# I2C register map
Vendor: Texas Instruments
Peripheral module from a debugger description file (folder CC2650).
Registers are 32-bit, access per field, reset 0x0 unless marked. A register's access mark holds for its fields unless they carry their own. Offsets are as the file gives them; lines under a group give offsets from that group; [hi:lo] are bit positions; {n}, {i} and the like mark numbered series; 'fields as' and 'values as' point back to an identical list; <NAME> marks a mode.

## I2C — I2CMaster/Slave Serial Controler
0x00 SOAR — Slave Own Address This register consists of seven address bits that identify this I2C device on the I2C bus.
  [6:0] OAR rw — I2C slave own address This field specifies bits a6 through a0 of the slave address.
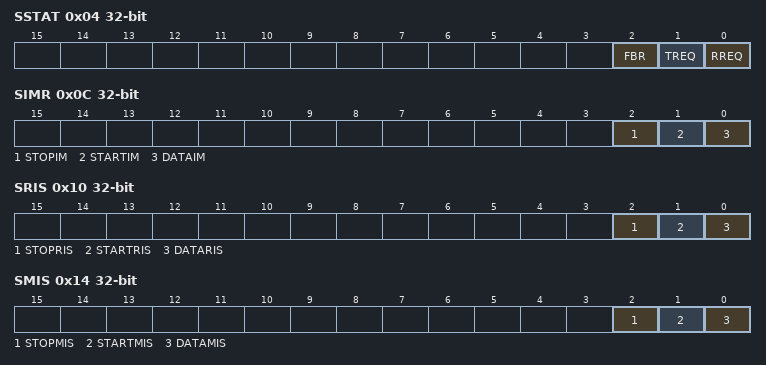
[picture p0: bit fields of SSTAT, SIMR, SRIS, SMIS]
0x04 SSTAT ro — Slave Status Internal Note: This register shares address with SCTL, meaning that this register functions as a control register when written, and a status register when read.
  [2] FBR — First byte received 0: The first byte has not been received. 1: The first byte following the slave's own address has been received. This bit is only valid when the RREQ bit is set and is automatically cleared when data has been read from the SDR register. Note: This bit is not used for slave transmit operations.
  [1] TREQ — Transmit request 0: No outstanding transmit request. 1: The I2C controller has been addressed as a slave transmitter and is using clock stretching to delay the master until data has been written to the SDR register.
  [0] RREQ — Receive request 0: No outstanding receive data 1: The I2C controller has outstanding receive data from the I2C master and is using clock stretching to delay the master until data has been read from the SDR register.
0x04 SCTL wo — Slave Control Note: This register shares address with SSTAT, meaning that this register functions as a control register when written, and a status register when read.
  [0] DA — Device active 0: Disables the I2C slave operation 1: Enables the I2C slave operation
0x08 SDR — Slave Data This register contains the data to be transmitted when in the Slave Transmit state, and the data received when in the Slave Receive state.
  [7:0] DATA rw — Data for transfer This field contains the data for transfer during a slave receive or transmit operation. When written the register data is used as transmit data. When read, this register returns the last data received. Data is stored until next update, either by a system write for transmit or by an external master for receive.
0x0C SIMR — Slave Interrupt Mask This register controls whether a raw interrupt is promoted to a controller interrupt.
  [2] STOPIM rw — Stop condition interrupt mask 0: The SRIS.STOPRIS interrupt is suppressed and not sent to the interrupt controller. 1: The SRIS.STOPRIS interrupt is enabled and sent to the interrupt controller.
    1=EN (Enable Interrupt); 0=DIS (Disable Interrupt)
  [1] STARTIM rw — Start condition interrupt mask 0: The SRIS.STARTRIS interrupt is suppressed and not sent to the interrupt controller. 1: The SRIS.STARTRIS interrupt is enabled and sent to the interrupt controller.
    1=EN (Enable Interrupt); 0=DIS (Disable Interrupt)
  [0] DATAIM rw — Data interrupt mask 0: The SRIS.DATARIS interrupt is suppressed and not sent to the interrupt controller. 1: The SRIS.DATARIS interrupt is enabled and sent to the interrupt controller.
0x10 SRIS ro — Slave Raw Interrupt Status This register shows the unmasked interrupt status.
  [2] STOPRIS — Stop condition raw interrupt status 0: No interrupt 1: A Stop condition interrupt is pending. This bit is cleared by writing a 1 to SICR.STOPIC.
  [1] STARTRIS — Start condition raw interrupt status 0: No interrupt 1: A Start condition interrupt is pending. This bit is cleared by writing a 1 to SICR.STARTIC.
  [0] DATARIS — Data raw interrupt status 0: No interrupt 1: A data received or data requested interrupt is pending. This bit is cleared by writing a 1 to the SICR.DATAIC.
0x14 SMIS ro — Slave Masked Interrupt Status This register show which interrupt is active (based on result from SRIS and SIMR).
  [2] STOPMIS — Stop condition masked interrupt status 0: An interrupt has not occurred or is masked/disabled. 1: An unmasked Stop condition interrupt is pending. This bit is cleared by writing a 1 to the SICR.STOPIC.
  [1] STARTMIS — Start condition masked interrupt status 0: An interrupt has not occurred or is masked/disabled. 1: An unmasked Start condition interrupt is pending. This bit is cleared by writing a 1 to the SICR.STARTIC.
  [0] DATAMIS — Data masked interrupt status 0: An interrupt has not occurred or is masked/disabled. 1: An unmasked data received or data requested interrupt is pending. This bit is cleared by writing a 1 to the SICR.DATAIC.
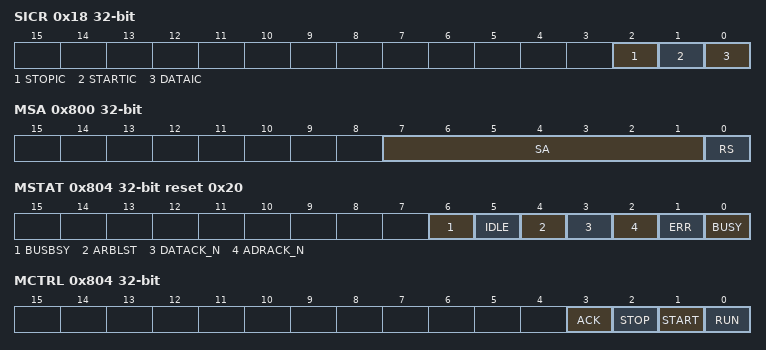
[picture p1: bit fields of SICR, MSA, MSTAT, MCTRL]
0x18 SICR wo — Slave Interrupt Clear This register clears the raw interrupt SRIS.
  [2] STOPIC — Stop condition interrupt clear Writing 1 to this bit clears SRIS.STOPRIS and SMIS.STOPMIS.
  [1] STARTIC — Start condition interrupt clear Writing 1 to this bit clears SRIS.STARTRIS SMIS.STARTMIS.
  [0] DATAIC — Data interrupt clear Writing 1 to this bit clears SRIS.DATARIS SMIS.DATAMIS.
0x800 MSA — Master Salve Address This register contains seven address bits of the slave to be accessed by the master (a6-a0), and an RS bit determining if the next operation is a receive or transmit.
  [7:1] SA rw — I2C master slave address Defines which slave is addressed for the transaction in master mode
  [0] RS rw — Receive or Send This bit-field specifies if the next operation is a receive (high) or a transmit/send (low) from the addressed slave SA.
    1=RX (Receive data from slave); 0=TX (Transmit/send data to slave)
0x804 MSTAT ro reset 0x20 — Master Status
  [6] BUSBSY — Bus busy 0: The I2C bus is idle. 1: The I2C bus is busy. The bit changes based on the MCTRL.START and MCTRL.STOP conditions.
  [5] IDLE — I2C idle 0: The I2C controller is not idle. 1: The I2C controller is idle.
  [4] ARBLST — Arbitration lost 0: The I2C controller won arbitration. 1: The I2C controller lost arbitration.
  [3] DATACK_N — Data Was Not Acknowledge 0: The transmitted data was acknowledged. 1: The transmitted data was not acknowledged.
  [2] ADRACK_N — Address Was Not Acknowledge 0: The transmitted address was acknowledged. 1: The transmitted address was not acknowledged.
  [1] ERR — Error 0: No error was detected on the last operation. 1: An error occurred on the last operation.
  [0] BUSY — I2C busy 0: The controller is idle. 1: The controller is busy. When this bit-field is set, the other status bits are not valid. Note: The I2C controller requires four SYSBUS clock cycles to assert the BUSY status after I2C master operation has been initiated through MCTRL register. Hence after programming MCTRL register, application is requested to wait for four SYSBUS clock cycles before issuing a controller status inquiry through MSTAT register. Any prior inquiry would result in wrong status being reported.
0x804 MCTRL wo — Master Control This register accesses status bits when read and control bits when written. When read, the status register indicates the state of the I2C bus controller as stated in MSTAT. When written, the control register configures the I2C controller operation. To generate a single transmit cycle, the I2C Master Slave Address (MSA) register is written with the desired address, the MSA.RS bit is cleared, and this register is written with * ACK=X (0 or 1), * STOP=1, * START=1, * RUN=1 to perform the operation and stop. When the operation is completed (or aborted due an error), an interrupt becomes active and the data may be read from the MDR register.
  [3] ACK — Data acknowledge enable 0: The received data byte is not acknowledged automatically by the master. 1: The received data byte is acknowledged automatically by the master. This bit-field must be cleared when the I2C bus controller requires no further data to be transmitted from the slave transmitter.
    1=EN (Enable acknowledge); 0=DIS (Disable acknowledge)
  [2] STOP — This bit-field determines if the cycle stops at the end of the data cycle or continues on to a repeated START condition. 0: The controller does not generate the Stop condition. 1: The controller generates the Stop condition.
    1=EN (Enable STOP); 0=DIS (Disable STOP)
  [1] START — This bit-field generates the Start or Repeated Start condition. 0: The controller does not generate the Start condition. 1: The controller generates the Start condition.
    1=EN (Enable START); 0=DIS (Disable START)
  [0] RUN — I2C master enable 0: The master is disabled. 1: The master is enabled to transmit or receive data.
    1=EN (Enable Master); 0=DIS (Disable Master)
0x808 MDR — Master Data This register contains the data to be transmitted when in the Master Transmit state and the data received when in the Master Receive state.
  [7:0] DATA rw — When Read: Last RX Data is returned When Written: Data is transferred during TX transaction
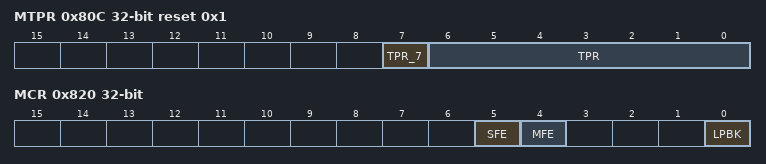
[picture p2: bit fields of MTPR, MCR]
0x80C MTPR reset 0x1 — I2C Master Timer Period This register specifies the period of the SCL clock.
  [7] TPR_7 rw — Must be set to 0 to set TPR. If set to 1, a write to TPR will be ignored.
  [6:0] TPR rw — SCL clock period This field specifies the period of the SCL clock. SCL_PRD = 2*(1+TPR)*(SCL_LP + SCL_HP)*CLK_PRD where: SCL_PRD is the SCL line period (I2C clock). TPR is the timer period register value (range of 1 to 127) SCL_LP is the SCL low period (fixed at 6). SCL_HP is the SCL high period (fixed at 4). CLK_PRD is the system clock period in ns.
0x810 MIMR — Master Interrupt Mask This register controls whether a raw interrupt is promoted to a controller interrupt.
  [0] IM rw — Interrupt mask 0: The MRIS.RIS interrupt is suppressed and not sent to the interrupt controller. 1: The master interrupt is sent to the interrupt controller when the MRIS.RIS is set.
    1=EN (Enable Interrupt); 0=DIS (Disable Interrupt)
0x814 MRIS ro — Master Raw Interrupt Status This register show the unmasked interrupt status.
  [0] RIS — Raw interrupt status 0: No interrupt 1: A master interrupt is pending. This bit is cleared by writing 1 to the MICR.IC bit .
0x818 MMIS ro — Master Masked Interrupt Status This register show which interrupt is active (based on result from MRIS and MIMR).
  [0] MIS — Masked interrupt status 0: An interrupt has not occurred or is masked. 1: A master interrupt is pending. This bit is cleared by writing 1 to the MICR.IC bit .
0x81C MICR wo — Master Interrupt Clear This register clears the raw and masked interrupt.
  [0] IC — Interrupt clear Writing 1 to this bit clears MRIS.RIS and MMIS.MIS . Reading this register returns no meaningful data.
0x820 MCR — Master Configuration This register configures the mode (Master or Slave) and sets the interface for test mode loopback.
  [5] SFE rw — I2C slave function enable
    1=EN (Slave mode is enabled.); 0=DIS (Slave mode is disabled.)
  [4] MFE rw — I2C master function enable
    1=EN (Master mode is enabled.); 0=DIS (Master mode is disabled.)
  [0] LPBK rw — I2C loopback 0: Normal operation 1: Loopback operation (test mode)
    1=EN (Enable Test Mode); 0=DIS (Disable Test Mode)
